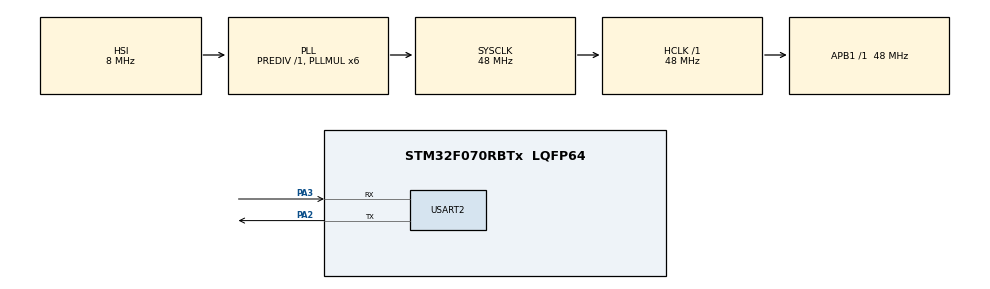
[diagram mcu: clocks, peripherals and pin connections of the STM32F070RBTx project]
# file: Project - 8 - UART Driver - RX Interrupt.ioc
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Mcu.Family=STM32F0
Mcu.Name=STM32F070RBTx
Mcu.Package=LQFP64
PA13.GPIO_Label=TMS
PA13.Mode=Serial_Wire
PA13.Signal=SYS_SWDIO
PA14.GPIO_Label=TCK
PA14.Mode=Serial_Wire
PA14.Signal=SYS_SWCLK
PA2.Mode=Asynchronous
PA2.Signal=USART2_TX
PA3.Mode=Asynchronous
PA3.Signal=USART2_RX
PC14-OSC32_IN.GPIO_Label=RCC_OSC32_IN
PC14-OSC32_IN.Mode=LSE-External-Oscillator
PC14-OSC32_IN.Signal=RCC_OSC32_IN
PC15-OSC32_OUT.GPIO_Label=RCC_OSC32_OUT
PC15-OSC32_OUT.Mode=LSE-External-Oscillator
PC15-OSC32_OUT.Signal=RCC_OSC32_OUT
PF0-OSC_IN.GPIO_Label=RCC_OSC_IN
PF0-OSC_IN.Mode=HSE-External-Clock-Source
PF0-OSC_IN.Signal=RCC_OSC_IN
PF1-OSC_OUT.GPIO_Label=RCC_OSC_OUT
PF1-OSC_OUT.Signal=RCC_OSC_OUT
ProjectManager.HeapSize=0x200
ProjectManager.StackSize=0x400
ProjectManager.TargetToolchain=STM32CubeIDE
RCC.AHBFreq_Value=48000000
RCC.APB1Freq_Value=48000000
RCC.APB1TimFreq_Value=48000000
RCC.HCLKFreq_Value=48000000
RCC.PLLMUL=RCC_PLL_MUL6
RCC.SYSCLKFreq_VALUE=48000000
RCC.SYSCLKSource=RCC_SYSCLKSOURCE_PLLCLK
USART2.VirtualMode-Asynchronous=VM_ASYNC
board=NUCLEO-F070RB

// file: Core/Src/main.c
/* USER CODE BEGIN Header */
/**
  ******************************************************************************
  * @file           : main.c
  * @brief          : Main program body
  ******************************************************************************
  * @attention
  *
  * <h2><center>&copy; Copyright (c) 2020 STMicroelectronics.
  * All rights reserved.</center></h2>
  *
  * This software component is licensed by ST under BSD 3-Clause license,
  * the "License"; You may not use this file except in compliance with the
  * License. You may obtain a copy of the License at:
  *                        opensource.org/licenses/BSD-3-Clause
  *
  ******************************************************************************
  */
/* USER CODE END Header */
#include "main.h"

/* USER CODE BEGIN Includes */
#include "uart_driver.h"
/* USER CODE END Includes */

UART_HandleTypeDef huart2;

void SystemClock_Config(void);
static void MX_GPIO_Init(void);
static void MX_USART2_UART_Init(void);

int main(void)
{

  /* MCU Configuration--------------------------------------------------------*/

  /* Reset of all peripherals, Initializes the Flash interface and the Systick. */
  HAL_Init();

  /* Configure the system clock */
  SystemClock_Config();

  /* Initialize all configured peripherals */
  MX_GPIO_Init();
  MX_USART2_UART_Init();
  /* USER CODE BEGIN 2 */
 UART_Init();
  /* USER CODE END 2 */

  /* Infinite loop */
  while (1)
  {

    /* USER CODE BEGIN 3 */
    int32_t byte = UART_read_byte();
    if (byte != -1)
    {
      UART_send_byte((uint8_t)byte);
    }
  }
  /* USER CODE END 3 */
}

void SystemClock_Config(void)
{
  RCC_OscInitTypeDef RCC_OscInitStruct = {0};
  RCC_ClkInitTypeDef RCC_ClkInitStruct = {0};

  /** Initializes the RCC Oscillators according to the specified parameters
  * in the RCC_OscInitTypeDef structure.
  */
  RCC_OscInitStruct.OscillatorType = RCC_OSCILLATORTYPE_HSI;
  RCC_OscInitStruct.HSIState = RCC_HSI_ON;
  RCC_OscInitStruct.HSICalibrationValue = RCC_HSICALIBRATION_DEFAULT;
  RCC_OscInitStruct.PLL.PLLState = RCC_PLL_ON;
  RCC_OscInitStruct.PLL.PLLSource = RCC_PLLSOURCE_HSI;
  RCC_OscInitStruct.PLL.PLLMUL = RCC_PLL_MUL6;
  RCC_OscInitStruct.PLL.PREDIV = RCC_PREDIV_DIV1;
  if (HAL_RCC_OscConfig(&RCC_OscInitStruct) != HAL_OK)
  {
    Error_Handler();
  }

  /** Initializes the CPU, AHB and APB buses clocks
  */
  RCC_ClkInitStruct.ClockType = RCC_CLOCKTYPE_HCLK|RCC_CLOCKTYPE_SYSCLK
                              |RCC_CLOCKTYPE_PCLK1;
  RCC_ClkInitStruct.SYSCLKSource = RCC_SYSCLKSOURCE_PLLCLK;
  RCC_ClkInitStruct.AHBCLKDivider = RCC_SYSCLK_DIV1;
  RCC_ClkInitStruct.APB1CLKDivider = RCC_HCLK_DIV1;

  if (HAL_RCC_ClockConfig(&RCC_ClkInitStruct, FLASH_LATENCY_1) != HAL_OK)
  {
    Error_Handler();
  }
}

static void MX_USART2_UART_Init(void)
{

  huart2.Instance = USART2;
  huart2.Init.BaudRate = 38400;
  huart2.Init.WordLength = UART_WORDLENGTH_8B;
  huart2.Init.StopBits = UART_STOPBITS_1;
  huart2.Init.Parity = UART_PARITY_NONE;
  huart2.Init.Mode = UART_MODE_TX_RX;
  huart2.Init.HwFlowCtl = UART_HWCONTROL_NONE;
  huart2.Init.OverSampling = UART_OVERSAMPLING_16;
  huart2.Init.OneBitSampling = UART_ONE_BIT_SAMPLE_DISABLE;
  huart2.AdvancedInit.AdvFeatureInit = UART_ADVFEATURE_NO_INIT;
  if (HAL_UART_Init(&huart2) != HAL_OK)
  {
    Error_Handler();
  }

}

static void MX_GPIO_Init(void)
{

  /* GPIO Ports Clock Enable */
  __HAL_RCC_GPIOC_CLK_ENABLE();
  __HAL_RCC_GPIOF_CLK_ENABLE();
  __HAL_RCC_GPIOA_CLK_ENABLE();

}

void Error_Handler(void)
{
}
